# STM32G553 register map
File version: 2.0.0
CPU: CM33 r0p4, little endian, MPU, FPU, 4 interrupt priority bits
Registers are 32-bit, read-write, reset 0x0 unless marked. A register's access mark holds for its fields unless they carry their own. Offsets are from the block's base; [hi:lo] are bit positions; 'fields as' and 'values as' point back to an identical list.

## TIM10 — TIM10 address block description
Base 0x40001C00
Same registers: TIM10_S 0x50001C00
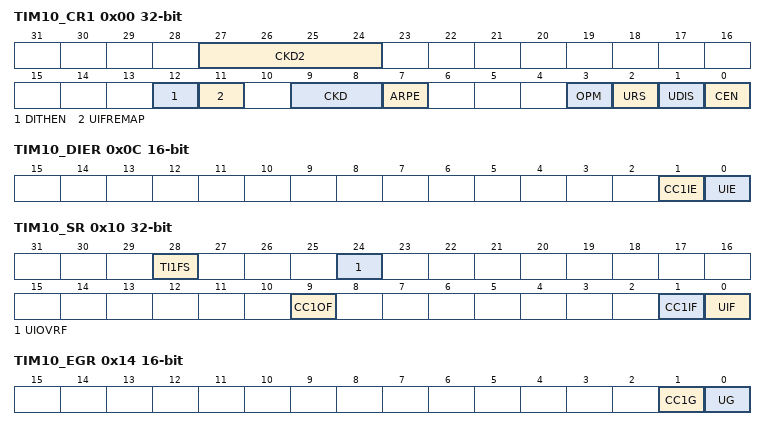
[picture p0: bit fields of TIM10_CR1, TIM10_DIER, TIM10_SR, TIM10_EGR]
0x00 TIM10_CR1 — TIM10 control register 1
  [27:24] CKD2 — Clock division 2
    0=No Division; 1=tless thansub>DTS2less than/sub> = 4xtless thansub>DTSless than/sub>; 2=tless thansub>DTS2less than/sub> = 16xtless thansub>DTSless than/sub>; 3=tless thansub>DTS2less than/sub> = 64xtless thansub>DTSless than/sub>; 4=tless thansub>DTS2less than/sub> = 256xtless thansub>DTSless than/sub>; 5=tless thansub>DTS2less than/sub> = 1024xtless thansub>DTSless than/sub>; 6=tless thansub>DTS2less than/sub> = 4096xtless thansub>DTSless than/sub>; 7=tless thansub>DTS2less than/sub> = 16384xtless thansub>DTSless than/sub>; 8=tless thansub>DTS2less than/sub> = 65536xtless thansub>DTSless than/sub>; 9=tless thansub>DTS2less than/sub> = 262144xtless thansub>DTSless than/sub>
  [12] DITHEN — Dithering enable
    0=Dithering disabled; 1=Dithering enabled
  [11] UIFREMAP — UIF status bit remapping
    0=No remapping. UIF status bit is not copied to TIMx_CNT register bit 31.; 1=Remapping enabled. UIF status bit is copied to TIMx_CNT register bit 31.
  [9:8] CKD — Clock division
    0=tless thansub>DTSless than/sub> = tless thansub>tim_ker_ckless than/sub>; 1=tless thansub>DTSless than/sub> = 2 x tless thansub>tim_ker_ckless than/sub>; 2=tless thansub>DTSless than/sub> = 4 x tless thansub>tim_ker_ckless than/sub>; 3=tless thansub>DTSless than/sub> = 8 x tless thansub>tim_ker_ckless than/sub>
  [7] ARPE — Auto-reload preload enable
    0=TIMx_ARR register is not buffered; 1=TIMx_ARR register is buffered
  [3] OPM — One-pulse mode
    0=Counter is not stopped on the update event; 1=Counter stops counting on the next update event (clearing the CEN bit)
  [2] URS — Update request source
    0=Any of the following events generate an UEV if enabled:; 1=Only counter overflow generates an UEV if enabled
  [1] UDIS — Update disable
    0=UEV enabled. An UEV is generated by one of the following events:; 1=UEV disabled. No UEV is generated, shadow registers keep their value (ARR, PSC, CCRx). The counter and the prescaler are reinitialized if the UG bit is set.
  [0] CEN — Counter enable
    0=Counter disabled; 1=Counter enabled
0x0C TIM10_DIER 16-bit — TIM10 interrupt enable register
  [1] CC1IE — Capture/Compare 1 interrupt enable
    0=CC1 interrupt disabled; 1=CC1 interrupt enabled
  [0] UIE — Update interrupt enable
    0=Update interrupt disabled; 1=Update interrupt enabled
0x10 TIM10_SR — TIM10 status register
  [28] TI1FS ro — tim_ti1f status
    0=tim_ti1f signal is low; 1=tim_ti1f signal is high
  [24] UIOVRF — Update Interrupt Overrun flag
    0=No Update Interrupt Overrun; 1=Update Interrupt Overrun
  [9] CC1OF — Capture/Compare 1 overcapture flag
    0=No overcapture has been detected; 1=The counter value has been captured in TIMx_CCR1 register while CC1IF flag was already set
  [1] CC1IF — Capture/compare 1 interrupt flag
    0=No compare match / No input capture occurred; 1=A compare match or an input capture occurred
  [0] UIF — Update interrupt flag
    0=No update occurred; 1=Update interrupt pending. This bit is set by hardware when the registers are updated:
0x14 TIM10_EGR 16-bit wo — TIM10 event generation register
  [1] CC1G — Capture/compare 1 generation
    0=No action; 1=A capture/compare event is generated on channel 1:
  [0] UG — Update generation
    0=No action; 1=Re-initialize the counter and generates an update of the registers. Note that the prescaler counter is cleared too (anyway the prescaler ratio is not affected). The counter is cleared.
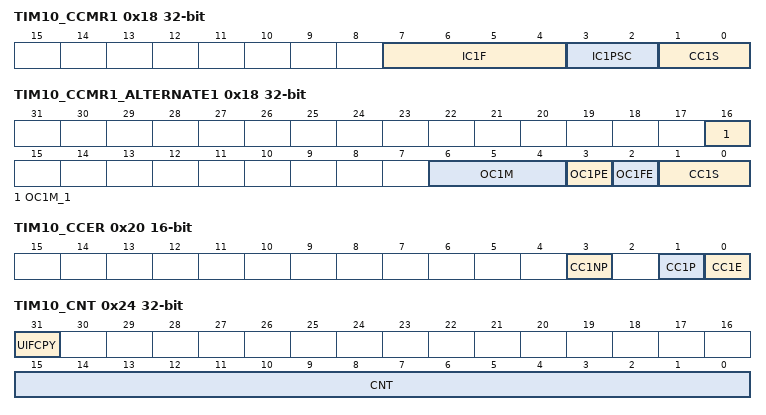
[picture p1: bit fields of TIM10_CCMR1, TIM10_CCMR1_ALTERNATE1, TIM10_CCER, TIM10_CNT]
0x18 TIM10_CCMR1 — TIM10 capture/compare mode register 1
  [7:4] IC1F — Input capture 1 filter
    0=No filter, sampling is done at fless thansub>DTSless than/sub>; 1=fless thansub>SAMPLINGless than/sub> = fless thansub>tim_ker_ckless than/sub>, N = 2; 2=fless thansub>SAMPLINGless than/sub> = fless thansub>tim_ker_ckless than/sub>, N = 4; 3=fless thansub>SAMPLINGless than/sub> = fless thansub>tim_ker_ckless than/sub>, N = 8; 4=fless thansub>SAMPLINGless than/sub> = fless thansub>DTSless than/sub>/2, N = 6; 5=fless thansub>SAMPLINGless than/sub> = fless thansub>DTSless than/sub>/2, N = 8; 6=fless thansub>SAMPLINGless than/sub> = fless thansub>DTSless than/sub>/4, N = 6; 7=fless thansub>SAMPLINGless than/sub> = fless thansub>DTSless than/sub>/4, N = 8; 8=fless thansub>SAMPLINGless than/sub> = fless thansub>DTSless than/sub>/8, N = 6; 9=fless thansub>SAMPLINGless than/sub> = fless thansub>DTSless than/sub>/8, N = 8; 10=fless thansub>SAMPLINGless than/sub> = fless thansub>DTSless than/sub>/16, N = 5; 11=fless thansub>SAMPLINGless than/sub> = fless thansub>DTSless than/sub>/16, N = 6; 12=fless thansub>SAMPLINGless than/sub> = fless thansub>DTSless than/sub>/16, N = 8; 13=fless thansub>SAMPLINGless than/sub> = fless thansub>DTSless than/sub>/32, N = 5; 14=fless thansub>SAMPLINGless than/sub> = fless thansub>DTSless than/sub>/32, N = 6; 15=fless thansub>SAMPLINGless than/sub> = fless thansub>DTSless than/sub>/32, N = 8
  [3:2] IC1PSC — Input capture 1 prescaler
    0=no prescaler, capture is done each time an edge is detected on the capture input; 1=capture is done once every 2 events; 2=capture is done once every 4 events; 3=capture is done once every 8 events
  [1:0] CC1S — Capture/Compare 1 selection
    0=CC1 channel is configured as output; 1=CC1 channel is configured as input, tim_ic1 is mapped on tim_ti1
0x18 TIM10_CCMR1_ALTERNATE1 (alternate view of TIM10_CCMR1) — TIM10 capture/compare mode register 1
  [16] OC1M_1 — OC1M[3]
  [6:4] OC1M — OC1M[2:0]: Output compare 1 mode (refer to bit 16 for OC1M[3])
    0=Frozen. The comparison between the output compare register TIMx_CCR1 and the counter TIMx_CNT has no effect on the outputs. This mode can be used when the timer serves as a software timebase. When the frozen mode is enabled during timer operation, the output keeps the state (active or inactive) it had before entering the frozen state.; 1=Set channel 1 to active level on match. tim_oc1ref signal is forced high when the counter TIMx_CNT matches the capture/compare register 1 (TIMx_CCR1).; 2=Set channel 1 to inactive level on match. tim_oc1ref signal is forced low when the counter TIMx_CNT matches the capture/compare register 1 (TIMx_CCR1).; 3=Toggle - tim_oc1ref toggles when TIMx_CNT = TIMx_CCR1; 4=Force inactive level - tim_oc1ref is forced low; 5=Force active level - tim_oc1ref is forced high; 6=PWM mode 1 - Channel 1 is active as long as TIMx_CNT less than TIMx_CCR1 else inactive; 7=PWM mode 2 - Channel 1 is inactive as long as TIMx_CNT less than TIMx_CCR1 else active
  [3] OC1PE — Output compare 1 preload enable
    0=Preload register on TIMx_CCR1 disabled. TIMx_CCR1 can be written at anytime, the new value is taken in account immediately.; 1=Preload register on TIMx_CCR1 enabled. Read/Write operations access the preload register. TIMx_CCR1 preload value is loaded in the active register at each update event.
  [2] OC1FE — Output compare 1 fast enable
    0=CC1 behaves normally depending on counter and CCR1 values even when the trigger is ON. The minimum delay to activate CC1 output when an edge occurs on the trigger input is 5 clock cycles.; 1=An active edge on the trigger input acts like a compare match on CC1 output. OC is then set to the compare level independently of the result of the comparison. Delay to sample the trigger input and to activate CC1 output is reduced to 3 clock cycles. OC1FE acts only if the channel is configured in PWM1 or PWM2 mode.
  [1:0] CC1S — Capture/Compare 1 selection
    values as TIM10_CCMR1.CC1S
0x20 TIM10_CCER 16-bit — TIM10 capture/compare enable register
  [3] CC1NP — Capture/Compare 1 complementary output Polarity.
  [1] CC1P — Capture/Compare 1 output Polarity.
    0=tim_oc1 active high (output mode) / Edge sensitivity selection (input mode, see below); 1=tim_oc1 active low (output mode) / Edge sensitivity selection (input mode, see below)
  [0] CC1E — Capture/Compare 1 output enable.
    0=Capture mode disabled / tim_oc1 is not active; 1=Capture mode enabled / tim_oc1 signal is output on the corresponding output pin
0x24 TIM10_CNT — TIM10 counter
  [31] UIFCPY — UIF Copy
  [15:0] CNT — Counter value
0x28 TIM10_PSC 16-bit — TIM10 prescaler
  [15:0] PSC — Prescaler value
0x2C TIM10_ARR reset 0xFFFF — TIM10 autoreload register
  [19:0] ARR — Auto-reload value
0x34 TIM10_CCR1 — TIM10 capture/compare register 1
  [19:0] CCR1 — Capture/compare 1 value
0x5C TIM10_TISEL 16-bit — TIM10 timer input selection register
  [3:0] TI1SEL — selects tim_ti1_in[15:0] input
    0=TIMx_CH1 input (tim_ti1_in0); 1=tim_ti1_in1; 15=tim_ti1_in15

## TIM11 — TIM11 address block description
Base 0x40002000
Same registers: TIM11_S 0x50002000
Registers as TIM10 (with TIM10 read as TIM11).

## TIM13 — TIM13 address block description
Base 0x40002800
Same registers: TIM13_S 0x50002800
Registers as TIM10 (with TIM10 read as TIM13).

## TIM14 — TIM14 address block description
Base 0x40002C00
Same registers: TIM14_S 0x50002C00
Registers as TIM10 (with TIM10 read as TIM14).
